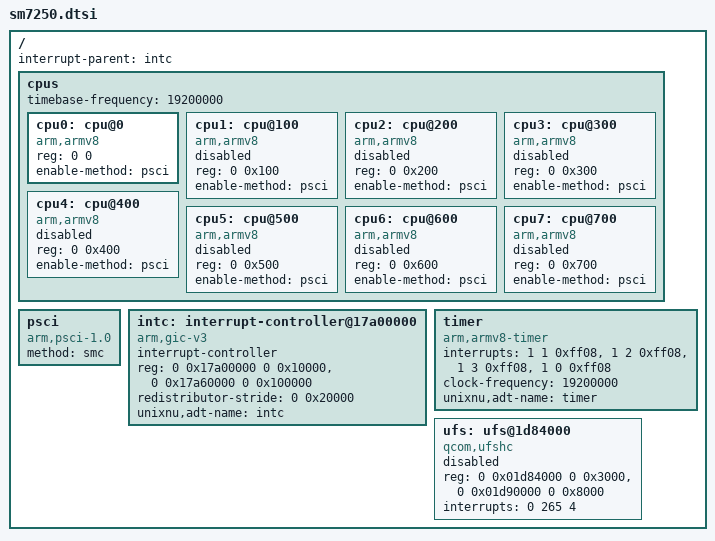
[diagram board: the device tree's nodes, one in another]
// SPDX-License-Identifier: BSD-2-Clause-Patent
// Independent transcription of facts from MiCode/kernel_devicetree
// 4eeaf08a0472a076aff622bb831dd19f53b1a56a:qcom/lito.dtsi.
// These nodes are a source inventory, not a firmware FDT.
/ {
    #address-cells = <2>;
    #size-cells = <2>;
    interrupt-parent = <&intc>;

    cpus {
        #address-cells = <2>;
        #size-cells = <0>;
        timebase-frequency = <19200000>;
        cpu0: cpu@0 { device_type = "cpu"; compatible = "arm,armv8"; reg = <0 0>; enable-method = "psci"; };
        cpu1: cpu@100 { device_type = "cpu"; compatible = "arm,armv8"; reg = <0 0x100>; enable-method = "psci"; status = "disabled"; };
        cpu2: cpu@200 { device_type = "cpu"; compatible = "arm,armv8"; reg = <0 0x200>; enable-method = "psci"; status = "disabled"; };
        cpu3: cpu@300 { device_type = "cpu"; compatible = "arm,armv8"; reg = <0 0x300>; enable-method = "psci"; status = "disabled"; };
        cpu4: cpu@400 { device_type = "cpu"; compatible = "arm,armv8"; reg = <0 0x400>; enable-method = "psci"; status = "disabled"; };
        cpu5: cpu@500 { device_type = "cpu"; compatible = "arm,armv8"; reg = <0 0x500>; enable-method = "psci"; status = "disabled"; };
        cpu6: cpu@600 { device_type = "cpu"; compatible = "arm,armv8"; reg = <0 0x600>; enable-method = "psci"; status = "disabled"; };
        cpu7: cpu@700 { device_type = "cpu"; compatible = "arm,armv8"; reg = <0 0x700>; enable-method = "psci"; status = "disabled"; };
    };

    psci { compatible = "arm,psci-1.0"; method = "smc"; };

    // Vendor root uses 32-bit cells here despite root widths of 2/2.
    // Express the same physical resources with valid root 64-bit tuples.
    intc: interrupt-controller@17a00000 {
        compatible = "arm,gic-v3";
        #address-cells = <0>;
        #interrupt-cells = <3>;
        interrupt-controller;
        reg = <0 0x17a00000 0 0x10000>, <0 0x17a60000 0 0x100000>;
        redistributor-stride = <0 0x20000>;
        unixnu,adt-name = "intc";
    };

    timer {
        compatible = "arm,armv8-timer";
        // Secure, physical nonsecure, virtual, hypervisor. PPI + 16 = INTID.
        interrupts = <1 1 0xff08>, <1 2 0xff08>, <1 3 0xff08>, <1 0 0xff08>;
        clock-frequency = <19200000>;
        unixnu,adt-name = "timer";
    };

    // Inventory only: UFS clocks, resets, regulators, PHY and SMMU need a port.
    ufs: ufs@1d84000 {
        compatible = "qcom,ufshc";
        reg = <0 0x01d84000 0 0x3000>, <0 0x01d90000 0 0x8000>;
        reg-names = "ufs_mem", "ufs_ice";
        interrupts = <0 265 4>;
        status = "disabled";
    };
};
